# alb32r003x register map
Vendor: ALB; Series: ALB RT SoC
CPU: ALB XF, little endian
Registers are 32-bit, access not given, reset 0x0 unless marked. A register's access mark holds for its fields unless they carry their own. Offsets are from the block's base; [hi:lo] are bit positions; {n}, {i} and the like mark numbered series.

## SMCM — SMCM_R: Redundant Secure Memory Control Module for fault-tolerant access protection
Base 0x23009000
0x00 ALLOCLOCK — ALLOCOCK: Atomic-lock register for exclusive access control to shared allocation resources
{0x4+4i} ALLOC{i} (i=0..4) — ALLOC{i}: Allocation entry {i} register defining memory-region base and size for secure/non-secure mapping
0x18 CTRL rw — CTRL: Global control register for module enable, mode selection and operational sequencing
  [0] alloc_en — Interface allocation configuration selection
    0=STATIC (Static configuration is determined by external signals); 1=DYNAMIC (Dynamic configuration is determined by the alloc register)
0x1C INIT — INIT: Initialization register triggering module reset and default configuration load
0x20 INITRAW — INITRAW: Raw initialization status register indicating unmasked hardware reset events
0x24 INITINTR — INITINTR: Initialization interrupt register enabling or disabling reset-completion notifications
0x28 INITSTAT — INITSTAT: Initialization status register reflecting current reset phase and completion flags
0x2C INSTOP rw — INSTOP: Instant-stop register for immediate module halt and emergency shutdown control
  [31:0] instop — After the system enters stop, the allocated sram banks are in a low-power state, with each corresponding to one sram bank(configured as 0 if not in use).
    0=LS (After the system enters stop, the corresponding sram bank enters LS mode); 1=DS (After the system enters stop, the corresponding sram bank enters DS mode)
0x30 OUTPUT rw — OUTPUT: Data output register driving external pins or peripheral bus lines
  [31:0] outstop — After the system exits stop, the allocated sram banks are in a low-power state, with each corresponding to one sram bank (configured as 0 if not in use).
    0=WORK (After the system exits stop, the corresponding sram bank enters the working mode); 1=LS (After the system exits stop, the corresponding sram bank enters LS mode)
0x34 INLS — INLS: Input level-select register choosing active-high or active-low polarity
0x38 OUTLS — OUTLS: Output level-select register setting push-pull or open-drain drive mode
0x3C OUTDS — OUTDS: Output drive-strength register configuring high-current or low-current capability
0x40 OUTSD — OUTSD: Output slew-rate register selecting fast or slow signal-edge shaping
0x3E0 FSLOCK — FSLOCK: Flash-security lock register controlling read-out and debug-access protection
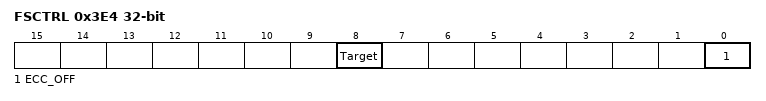
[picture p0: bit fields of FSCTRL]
0x3E4 FSCTRL rw — FSCTRL: Flash-sequence control register initiating program/erase operations and status polling
  [8] Target — Functional safety objective
    0=INFERFACE (Interface register); 1=MEMORY
  [0] ECC_OFF — Disable ECC check
    0=ENABLED (Enable all bank ECC validations); 1=DISABLED (Disable all bank ECC validations)
0x3E8 FSDATA — FSDATA: Flash-sector data register for temporary storage during program/verify operations
0x3EC FSINFO — FSINFO: Flash-sector information register providing erase-state and protection status
0x3F0 PARAM1 — PARAM1: Device-parameter register 1 supplying silicon-specific timing and geometry constants
0x3F4 PARAM2 ro — PARAM2: Device-parameter register 2 delivering additional flash-timing and voltage parameters
  [0] DW — The parameter value of DW
    0=DW=32; 1=DW=64
0x3F8 PARAM3 — PARAM3: Device-parameter register 3 conveying extended feature and geometry information
0x3FC REV — REV: Revision register returning the current IP core version and metal-layer revision

## GPIO1 — GPIO1: General-purpose I/O port 1 configurable as input, output, or alternate peripheral function
Base 0x25000000
Same registers: GPIO2 0x25001000, GPIO3 0x25007000, GPIO4 0x25008000, GPIO5 0x25009000
0x00 gpio_swporta_dr — Port A data register. Stores the output data for Port A.
0x04 gpio_swporta_ddr rw — Port A data direction register. Configures Port A as input or output.
  [27:0] Port A Data Direction Register
    0=Input (Configures as input.); 1=Output (Configures as output.)
0x08 gpio_porta_ctl rw — Port A data source register. Selects data/control source (software or hardware).
  [27:0] Port A Data Source Register — Port A data source register. Selects data/control source.
    0=Software (Data/control source is software.); 1=Hardware (Data/control source is hardware.)
0x30 gpio_inten rw — Interrupt enable register. Configures each Port A bit as interrupt or GPIO signal.
  [31:0] Interrupt enable
    0=Disabled (Interrupt disabled.); 1=Enabled (Interrupt enabled.)
0x34 gpio_intmask rw — Interrupt mask register. Masks or unmasks interrupts for Port A.
  [31:0] Interrupt mask
    0=Masked (Interrupt is masked.); 1=Unmasked (Interrupt is unmasked.)
0x38 gpio_inttype_level rw — Interrupt level register. Configures interrupt type as level-sensitive or edge-sensitive.
  [31:0] Interrupt level — Interrupt level register. Configures interrupt type.
    0=LevelSensitive (Interrupt is level-sensitive.); 1=EdgeSensitive (Interrupt is edge-sensitive.)
0x3C gpio_int_polarity rw — Interrupt polarity register. Configures sensitivity (active-low/falling-edge or active-high/rising-edge).
  [31:0] Interrupt polarity — Interrupt polarity register. Configures sensitivity type.
    0=Active low or falling edge; 1=Active high or rising edge
0x40 gpio_intstatus — Interrupt status register. Reports the interrupt status of Port A.
0x44 gpio_rawintstatus — Raw interrupt status register. Reports raw (pre-masked) interrupt status of Port A.
0x48 gpio_debounce rw — Debounce enable register. Controls debounce circuitry for interrupt signals.
  [31:0] Debounce enable
    0=Disabled (Debounce is disabled.); 1=Enabled (Debounce is enabled.)
0x4C gpio_porta_eoi — Port A clear interrupt register. Clears edge-detected interrupts for Port A.
0x50 gpio_ext_porta — Port A external port register. Reads input signal values or the output data register.
0x60 gpio_ls_sync rw — Level-sensitive synchronization enable register. Synchronizes level-sensitive interrupts to pclk_intr.
  [0] gpio_ls_sync — Level-sensitive synchronization enable register. Synchronizes interrupts to pclk_intr.
    0=Disabled (Synchronization is disabled.); 1=Enabled (Synchronization is enabled.)
0x64 GPIO_ID_CODE
0x68 GPIO_INT_BOTHEDGE rw — Interrupt Both Edge type
  [0] GPIO_INT_BOTHEDGE — Controls the edge type of interrupt that can occur on Part A
    0=DISABLED (single edge senitive); 1=ENABLED (both edge senitive)
0x6C GPIO_VER_ID_CODE — GPIO Component Version
0x70 GPIO_CONFIG_REG2 — GPIO Configuration Register2
0x74 GPIO_CONFIG_REF1 — GPIO Configuration Register1
